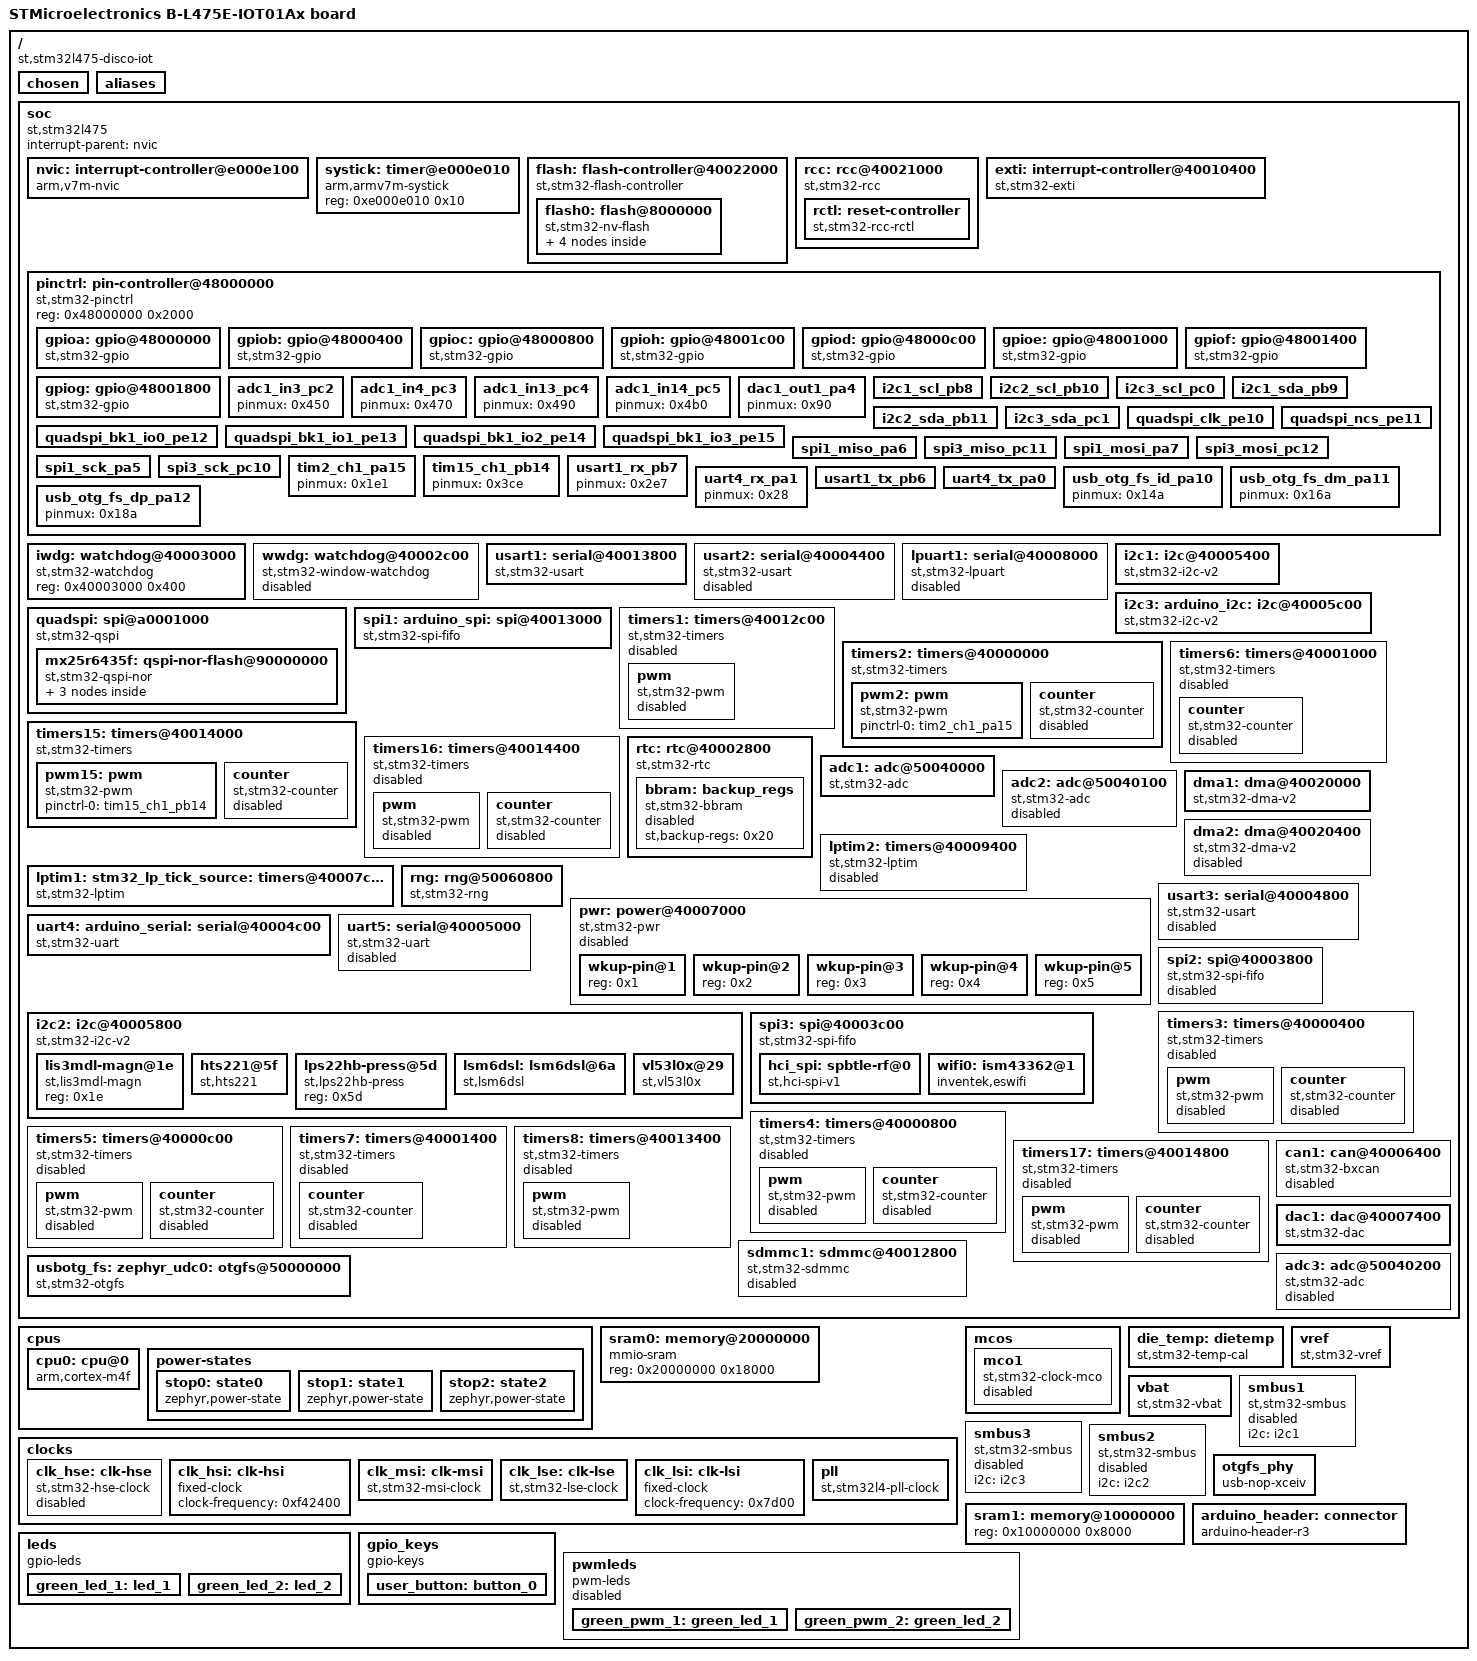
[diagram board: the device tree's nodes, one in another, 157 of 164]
/dts-v1/;

/ {
	#address-cells = < 0x1 >;
	#size-cells = < 0x1 >;
	model = "STMicroelectronics B-L475E-IOT01Ax board";
	compatible = "st,stm32l475-disco-iot";
	chosen {
		zephyr,entropy = &rng;
		zephyr,flash-controller = &mx25r6435f;
		zephyr,console = &usart1;
		zephyr,shell-uart = &usart1;
		zephyr,sram = &sram0;
		zephyr,flash = &flash0;
		zephyr,code-partition = &slot0_partition;
		zephyr,bt-c2h-uart = &usart1;
		zephyr,bt-hci = &hci_spi;
	};
	aliases {
		led0 = &green_led_2;
		led1 = &green_led_1;
		pwm-led0 = &green_pwm_2;
		pwm-led1 = &green_pwm_1;
		sw0 = &user_button;
		eswifi0 = &wifi0;
		watchdog0 = &iwdg;
		accel0 = &lsm6dsl;
		volt-sensor0 = &vref;
		volt-sensor1 = &vbat;
		die-temp0 = &die_temp;
	};
	soc {
		#address-cells = < 0x1 >;
		#size-cells = < 0x1 >;
		compatible = "st,stm32l475", "st,stm32l4", "simple-bus";
		interrupt-parent = < &nvic >;
		ranges;
		nvic: interrupt-controller@e000e100 {
			#address-cells = < 0x1 >;
			compatible = "arm,v7m-nvic";
			reg = < 0xe000e100 0xc00 >;
			interrupt-controller;
			#interrupt-cells = < 0x2 >;
			arm,num-irq-priority-bits = < 0x4 >;
			phandle = < 0x1 >;
		};
		systick: timer@e000e010 {
			compatible = "arm,armv7m-systick";
			reg = < 0xe000e010 0x10 >;
		};
		flash: flash-controller@40022000 {
			compatible = "st,stm32-flash-controller", "st,stm32l4-flash-controller";
			reg = < 0x40022000 0x400 >;
			interrupts = < 0x4 0x0 >;
			clocks = < &rcc 0x48 0x100 >;
			#address-cells = < 0x1 >;
			#size-cells = < 0x1 >;
			flash0: flash@8000000 {
				compatible = "st,stm32-nv-flash", "soc-nv-flash";
				write-block-size = < 0x8 >;
				erase-block-size = < 0x800 >;
				max-erase-time = < 0x19 >;
				reg = < 0x8000000 0x100000 >;
				partitions {
					compatible = "fixed-partitions";
					#address-cells = < 0x1 >;
					#size-cells = < 0x1 >;
					boot_partition: partition@0 {
						label = "mcuboot";
						reg = < 0x0 0x10000 >;
						read-only;
					};
					slot0_partition: partition@1000 {
						label = "image-0";
						reg = < 0x1000 0xe8000 >;
					};
					storage_partition: partition@f8000 {
						label = "storage";
						reg = < 0xf8000 0x8000 >;
					};
				};
			};
		};
		rcc: rcc@40021000 {
			compatible = "st,stm32-rcc";
			#clock-cells = < 0x2 >;
			reg = < 0x40021000 0x400 >;
			clocks = < &pll >;
			clock-frequency = < 0x4c4b400 >;
			ahb-prescaler = < 0x1 >;
			apb1-prescaler = < 0x1 >;
			apb2-prescaler = < 0x1 >;
			phandle = < 0x2 >;
			rctl: reset-controller {
				compatible = "st,stm32-rcc-rctl";
				#reset-cells = < 0x1 >;
				phandle = < 0x4 >;
			};
		};
		exti: interrupt-controller@40010400 {
			compatible = "st,stm32-exti";
			interrupt-controller;
			#interrupt-cells = < 0x1 >;
			#address-cells = < 0x1 >;
			reg = < 0x40010400 0x400 >;
			num-lines = < 0x10 >;
			interrupts = < 0x6 0x0 >, < 0x7 0x0 >, < 0x8 0x0 >, < 0x9 0x0 >, < 0xa 0x0 >, < 0x17 0x0 >, < 0x28 0x0 >;
			interrupt-names = "line0", "line1", "line2", "line3", "line4", "line5-9", "line10-15";
			line-ranges = < 0x0 0x1 >, < 0x1 0x1 >, < 0x2 0x1 >, < 0x3 0x1 >, < 0x4 0x1 >, < 0x5 0x5 >, < 0xa 0x6 >;
		};
		pinctrl: pin-controller@48000000 {
			compatible = "st,stm32-pinctrl";
			#address-cells = < 0x1 >;
			#size-cells = < 0x1 >;
			reg = < 0x48000000 0x2000 >;
			gpioa: gpio@48000000 {
				compatible = "st,stm32-gpio";
				gpio-controller;
				#gpio-cells = < 0x2 >;
				reg = < 0x48000000 0x400 >;
				clocks = < &rcc 0x4c 0x1 >;
				phandle = < 0x15 >;
			};
			gpiob: gpio@48000400 {
				compatible = "st,stm32-gpio";
				gpio-controller;
				#gpio-cells = < 0x2 >;
				reg = < 0x48000400 0x400 >;
				clocks = < &rcc 0x4c 0x2 >;
				phandle = < 0x26 >;
			};
			gpioc: gpio@48000800 {
				compatible = "st,stm32-gpio";
				gpio-controller;
				#gpio-cells = < 0x2 >;
				reg = < 0x48000800 0x400 >;
				clocks = < &rcc 0x4c 0x4 >;
				phandle = < 0x21 >;
			};
			gpioh: gpio@48001c00 {
				compatible = "st,stm32-gpio";
				gpio-controller;
				#gpio-cells = < 0x2 >;
				reg = < 0x48001c00 0x400 >;
				clocks = < &rcc 0x4c 0x80 >;
			};
			gpiod: gpio@48000c00 {
				compatible = "st,stm32-gpio";
				gpio-controller;
				#gpio-cells = < 0x2 >;
				reg = < 0x48000c00 0x400 >;
				clocks = < &rcc 0x4c 0x8 >;
				phandle = < 0x20 >;
			};
			gpioe: gpio@48001000 {
				compatible = "st,stm32-gpio";
				gpio-controller;
				#gpio-cells = < 0x2 >;
				reg = < 0x48001000 0x400 >;
				clocks = < &rcc 0x4c 0x10 >;
				phandle = < 0x25 >;
			};
			gpiof: gpio@48001400 {
				compatible = "st,stm32-gpio";
				gpio-controller;
				#gpio-cells = < 0x2 >;
				reg = < 0x48001400 0x400 >;
				clocks = < &rcc 0x4c 0x20 >;
			};
			gpiog: gpio@48001800 {
				compatible = "st,stm32-gpio";
				gpio-controller;
				#gpio-cells = < 0x2 >;
				reg = < 0x48001800 0x400 >;
				clocks = < &rcc 0x4c 0x40 >;
			};
			adc1_in3_pc2: adc1_in3_pc2 {
				pinmux = < 0x450 >;
				phandle = < 0x18 >;
			};
			adc1_in4_pc3: adc1_in4_pc3 {
				pinmux = < 0x470 >;
				phandle = < 0x19 >;
			};
			adc1_in13_pc4: adc1_in13_pc4 {
				pinmux = < 0x490 >;
				phandle = < 0x1a >;
			};
			adc1_in14_pc5: adc1_in14_pc5 {
				pinmux = < 0x4b0 >;
				phandle = < 0x1b >;
			};
			dac1_out1_pa4: dac1_out1_pa4 {
				pinmux = < 0x90 >;
				phandle = < 0x27 >;
			};
			i2c1_scl_pb8: i2c1_scl_pb8 {
				pinmux = < 0x304 >;
				bias-pull-up;
				drive-open-drain;
				phandle = < 0x7 >;
			};
			i2c2_scl_pb10: i2c2_scl_pb10 {
				pinmux = < 0x344 >;
				bias-pull-up;
				drive-open-drain;
				phandle = < 0x1e >;
			};
			i2c3_scl_pc0: i2c3_scl_pc0 {
				pinmux = < 0x404 >;
				bias-pull-up;
				drive-open-drain;
				phandle = < 0x9 >;
			};
			i2c1_sda_pb9: i2c1_sda_pb9 {
				pinmux = < 0x324 >;
				bias-pull-up;
				drive-open-drain;
				phandle = < 0x8 >;
			};
			i2c2_sda_pb11: i2c2_sda_pb11 {
				pinmux = < 0x364 >;
				bias-pull-up;
				drive-open-drain;
				phandle = < 0x1f >;
			};
			i2c3_sda_pc1: i2c3_sda_pc1 {
				pinmux = < 0x424 >;
				bias-pull-up;
				drive-open-drain;
				phandle = < 0xa >;
			};
			quadspi_clk_pe10: quadspi_clk_pe10 {
				pinmux = < 0x94a >;
				slew-rate = "very-high-speed";
				phandle = < 0xb >;
			};
			quadspi_ncs_pe11: quadspi_ncs_pe11 {
				pinmux = < 0x96a >;
				slew-rate = "very-high-speed";
				phandle = < 0xc >;
			};
			quadspi_bk1_io0_pe12: quadspi_bk1_io0_pe12 {
				pinmux = < 0x98a >;
				slew-rate = "very-high-speed";
				phandle = < 0xd >;
			};
			quadspi_bk1_io1_pe13: quadspi_bk1_io1_pe13 {
				pinmux = < 0x9aa >;
				slew-rate = "very-high-speed";
				phandle = < 0xe >;
			};
			quadspi_bk1_io2_pe14: quadspi_bk1_io2_pe14 {
				pinmux = < 0x9ca >;
				slew-rate = "very-high-speed";
				phandle = < 0xf >;
			};
			quadspi_bk1_io3_pe15: quadspi_bk1_io3_pe15 {
				pinmux = < 0x9ea >;
				slew-rate = "very-high-speed";
				phandle = < 0x10 >;
			};
			spi1_miso_pa6: spi1_miso_pa6 {
				pinmux = < 0xc5 >;
				bias-pull-down;
				phandle = < 0x13 >;
			};
			spi3_miso_pc11: spi3_miso_pc11 {
				pinmux = < 0x566 >;
				bias-pull-down;
				slew-rate = "very-high-speed";
				phandle = < 0x23 >;
			};
			spi1_mosi_pa7: spi1_mosi_pa7 {
				pinmux = < 0xe5 >;
				bias-pull-down;
				phandle = < 0x14 >;
			};
			spi3_mosi_pc12: spi3_mosi_pc12 {
				pinmux = < 0x586 >;
				bias-pull-down;
				phandle = < 0x24 >;
			};
			spi1_sck_pa5: spi1_sck_pa5 {
				pinmux = < 0xa5 >;
				bias-pull-down;
				slew-rate = "very-high-speed";
				phandle = < 0x12 >;
			};
			spi3_sck_pc10: spi3_sck_pc10 {
				pinmux = < 0x546 >;
				bias-pull-down;
				slew-rate = "very-high-speed";
				phandle = < 0x22 >;
			};
			tim2_ch1_pa15: tim2_ch1_pa15 {
				pinmux = < 0x1e1 >;
				phandle = < 0x16 >;
			};
			tim15_ch1_pb14: tim15_ch1_pb14 {
				pinmux = < 0x3ce >;
				phandle = < 0x17 >;
			};
			usart1_rx_pb7: usart1_rx_pb7 {
				pinmux = < 0x2e7 >;
				phandle = < 0x6 >;
			};
			uart4_rx_pa1: uart4_rx_pa1 {
				pinmux = < 0x28 >;
				phandle = < 0x1d >;
			};
			usart1_tx_pb6: usart1_tx_pb6 {
				pinmux = < 0x2c7 >;
				bias-pull-up;
				phandle = < 0x5 >;
			};
			uart4_tx_pa0: uart4_tx_pa0 {
				pinmux = < 0x8 >;
				bias-pull-up;
				phandle = < 0x1c >;
			};
			usb_otg_fs_id_pa10: usb_otg_fs_id_pa10 {
				pinmux = < 0x14a >;
				phandle = < 0x2b >;
			};
			usb_otg_fs_dm_pa11: usb_otg_fs_dm_pa11 {
				pinmux = < 0x16a >;
				phandle = < 0x29 >;
			};
			usb_otg_fs_dp_pa12: usb_otg_fs_dp_pa12 {
				pinmux = < 0x18a >;
				phandle = < 0x2a >;
			};
		};
		iwdg: watchdog@40003000 {
			compatible = "st,stm32-watchdog";
			reg = < 0x40003000 0x400 >;
			status = "okay";
		};
		wwdg: watchdog@40002c00 {
			compatible = "st,stm32-window-watchdog";
			reg = < 0x40002c00 0x400 >;
			clocks = < &rcc 0x58 0x800 >;
			interrupts = < 0x0 0x7 >;
			status = "disabled";
		};
		usart1: serial@40013800 {
			compatible = "st,stm32-usart", "st,stm32-uart";
			reg = < 0x40013800 0x400 >;
			clocks = < &rcc 0x60 0x4000 >;
			resets = < &rctl 0x80e >;
			interrupts = < 0x25 0x0 >;
			status = "okay";
			current-speed = < 0x1c200 >;
			pinctrl-0 = < &usart1_tx_pb6 &usart1_rx_pb7 >;
			pinctrl-names = "default";
		};
		usart2: serial@40004400 {
			compatible = "st,stm32-usart", "st,stm32-uart";
			reg = < 0x40004400 0x400 >;
			clocks = < &rcc 0x58 0x20000 >;
			resets = < &rctl 0x711 >;
			interrupts = < 0x26 0x0 >;
			status = "disabled";
		};
		lpuart1: serial@40008000 {
			compatible = "st,stm32-lpuart", "st,stm32-uart";
			reg = < 0x40008000 0x400 >;
			clocks = < &rcc 0x5c 0x1 >;
			resets = < &rctl 0x780 >;
			interrupts = < 0x46 0x0 >;
			status = "disabled";
		};
		i2c1: i2c@40005400 {
			compatible = "st,stm32-i2c-v2";
			clock-frequency = < 0x61a80 >;
			#address-cells = < 0x1 >;
			#size-cells = < 0x0 >;
			reg = < 0x40005400 0x400 >;
			clocks = < &rcc 0x58 0x200000 >;
			interrupts = < 0x1f 0x0 >, < 0x20 0x0 >;
			interrupt-names = "event", "error";
			status = "okay";
			pinctrl-0 = < &i2c1_scl_pb8 &i2c1_sda_pb9 >;
			pinctrl-names = "default";
			phandle = < 0x31 >;
		};
		i2c3: arduino_i2c: i2c@40005c00 {
			compatible = "st,stm32-i2c-v2";
			clock-frequency = < 0x61a80 >;
			#address-cells = < 0x1 >;
			#size-cells = < 0x0 >;
			reg = < 0x40005c00 0x400 >;
			clocks = < &rcc 0x58 0x800000 >;
			interrupts = < 0x48 0x0 >, < 0x49 0x0 >;
			interrupt-names = "event", "error";
			status = "okay";
			pinctrl-0 = < &i2c3_scl_pc0 &i2c3_sda_pc1 >;
			pinctrl-names = "default";
			phandle = < 0x32 >;
		};
		quadspi: spi@a0001000 {
			compatible = "st,stm32-qspi";
			#address-cells = < 0x1 >;
			#size-cells = < 0x0 >;
			reg = < 0xa0001000 0x400 >;
			interrupts = < 0x47 0x0 >;
			clocks = < &rcc 0x50 0x100 >;
			status = "okay";
			pinctrl-0 = < &quadspi_clk_pe10 &quadspi_ncs_pe11 &quadspi_bk1_io0_pe12 &quadspi_bk1_io1_pe13 &quadspi_bk1_io2_pe14 &quadspi_bk1_io3_pe15 >;
			pinctrl-names = "default";
			dmas = < &dma1 0x5 0x5 0x0 >;
			dma-names = "tx_rx";
			mx25r6435f: qspi-nor-flash@90000000 {
				compatible = "st,stm32-qspi-nor";
				reg = < 0x90000000 0x800000 >;
				qspi-max-frequency = < 0x2faf080 >;
				status = "okay";
				partitions {
					compatible = "fixed-partitions";
					#address-cells = < 0x1 >;
					#size-cells = < 0x1 >;
					slot1_partition: partition@0 {
						label = "image-1";
						reg = < 0x0 0xd8000 >;
					};
					slot2_partition: partition@d8000 {
						label = "image-3";
						reg = < 0xd8000 0x700000 >;
					};
				};
			};
		};
		spi1: arduino_spi: spi@40013000 {
			compatible = "st,stm32-spi-fifo", "st,stm32-spi";
			#address-cells = < 0x1 >;
			#size-cells = < 0x0 >;
			reg = < 0x40013000 0x400 >;
			interrupts = < 0x23 0x5 >;
			clocks = < &rcc 0x60 0x1000 >;
			status = "okay";
			pinctrl-0 = < &spi1_sck_pa5 &spi1_miso_pa6 &spi1_mosi_pa7 >;
			pinctrl-names = "default";
			cs-gpios = < &gpioa 0x2 0x11 >;
		};
		timers1: timers@40012c00 {
			compatible = "st,stm32-timers";
			reg = < 0x40012c00 0x400 >;
			clocks = < &rcc 0x60 0x800 >;
			resets = < &rctl 0x80b >;
			interrupts = < 0x18 0x0 >, < 0x19 0x0 >, < 0x1a 0x0 >, < 0x1b 0x0 >;
			interrupt-names = "brk", "up", "trgcom", "cc";
			st,prescaler = < 0x0 >;
			status = "disabled";
			pwm {
				compatible = "st,stm32-pwm";
				status = "disabled";
				#pwm-cells = < 0x3 >;
			};
		};
		timers2: timers@40000000 {
			compatible = "st,stm32-timers";
			reg = < 0x40000000 0x400 >;
			clocks = < &rcc 0x58 0x1 >;
			resets = < &rctl 0x700 >;
			interrupts = < 0x1c 0x0 >;
			interrupt-names = "global";
			st,prescaler = < 0x2710 >;
			status = "okay";
			pwm2: pwm {
				compatible = "st,stm32-pwm";
				status = "okay";
				#pwm-cells = < 0x3 >;
				pinctrl-0 = < &tim2_ch1_pa15 >;
				pinctrl-names = "default";
				phandle = < 0x34 >;
			};
			counter {
				compatible = "st,stm32-counter";
				status = "disabled";
			};
		};
		timers6: timers@40001000 {
			compatible = "st,stm32-timers";
			reg = < 0x40001000 0x400 >;
			clocks = < &rcc 0x58 0x10 >;
			resets = < &rctl 0x704 >;
			interrupts = < 0x36 0x0 >;
			interrupt-names = "global";
			st,prescaler = < 0x0 >;
			status = "disabled";
			counter {
				compatible = "st,stm32-counter";
				status = "disabled";
			};
		};
		timers15: timers@40014000 {
			compatible = "st,stm32-timers";
			reg = < 0x40014000 0x400 >;
			clocks = < &rcc 0x60 0x10000 >;
			resets = < &rctl 0x810 >;
			interrupts = < 0x18 0x0 >;
			interrupt-names = "global";
			st,prescaler = < 0x2710 >;
			status = "okay";
			pwm15: pwm {
				compatible = "st,stm32-pwm";
				status = "okay";
				#pwm-cells = < 0x3 >;
				pinctrl-0 = < &tim15_ch1_pb14 >;
				pinctrl-names = "default";
				phandle = < 0x35 >;
			};
			counter {
				compatible = "st,stm32-counter";
				status = "disabled";
			};
		};
		timers16: timers@40014400 {
			compatible = "st,stm32-timers";
			reg = < 0x40014400 0x400 >;
			clocks = < &rcc 0x60 0x20000 >;
			resets = < &rctl 0x811 >;
			interrupts = < 0x19 0x0 >;
			interrupt-names = "global";
			st,prescaler = < 0x0 >;
			status = "disabled";
			pwm {
				compatible = "st,stm32-pwm";
				status = "disabled";
				#pwm-cells = < 0x3 >;
			};
			counter {
				compatible = "st,stm32-counter";
				status = "disabled";
			};
		};
		rtc: rtc@40002800 {
			compatible = "st,stm32-rtc";
			reg = < 0x40002800 0x400 >;
			interrupts = < 0x29 0x0 >;
			clocks = < &rcc 0x58 0x10000000 >, < &rcc 0x3 0x10c80090 >;
			prescaler = < 0x8000 >;
			alarms-count = < 0x2 >;
			alrm-exti-line = < 0x12 >;
			status = "okay";
			bbram: backup_regs {
				compatible = "st,stm32-bbram";
				st,backup-regs = < 0x20 >;
				status = "disabled";
			};
		};
		adc1: adc@50040000 {
			compatible = "st,stm32-adc";
			reg = < 0x50040000 0x100 >;
			clocks = < &rcc 0x4c 0x2000 >;
			interrupts = < 0x12 0x0 >;
			status = "okay";
			#io-channel-cells = < 0x1 >;
			resolutions = < 0x60630c 0x51630c 0x42630c 0x33630c >;
			sampling-times = < 0x3 0x7 0xd 0x19 0x30 0x5d 0xf8 0x281 >;
			st,adc-sequencer = "FULLY_CONFIGURABLE";
			st,adc-oversampler = "OVERSAMPLER_MINIMAL";
			pinctrl-0 = < &adc1_in3_pc2 &adc1_in4_pc3 &adc1_in13_pc4 &adc1_in14_pc5 >;
			pinctrl-names = "default";
			st,adc-clock-source = "SYNC";
			st,adc-prescaler = < 0x4 >;
			phandle = < 0x30 >;
		};
		adc2: adc@50040100 {
			compatible = "st,stm32-adc";
			reg = < 0x50040100 0x100 >;
			clocks = < &rcc 0x4c 0x2000 >;
			interrupts = < 0x12 0x0 >;
			status = "disabled";
			#io-channel-cells = < 0x1 >;
			resolutions = < 0x60630c 0x51630c 0x42630c 0x33630c >;
			sampling-times = < 0x3 0x7 0xd 0x19 0x30 0x5d 0xf8 0x281 >;
			st,adc-sequencer = "FULLY_CONFIGURABLE";
			st,adc-oversampler = "OVERSAMPLER_MINIMAL";
		};
		dma1: dma@40020000 {
			compatible = "st,stm32-dma-v2";
			#dma-cells = < 0x3 >;
			reg = < 0x40020000 0x400 >;
			interrupts = < 0xb 0x0 0xc 0x0 0xd 0x0 0xe 0x0 0xf 0x0 0x10 0x0 0x11 0x0 >;
			clocks = < &rcc 0x48 0x1 >;
			dma-requests = < 0x7 >;
			status = "okay";
			phandle = < 0x11 >;
		};
		dma2: dma@40020400 {
			compatible = "st,stm32-dma-v2";
			#dma-cells = < 0x3 >;
			reg = < 0x40020400 0x400 >;
			interrupts = < 0x38 0x0 0x39 0x0 0x3a 0x0 0x3b 0x0 0x3c 0x0 0x44 0x0 0x45 0x0 >;
			clocks = < &rcc 0x48 0x2 >;
			dma-requests = < 0x7 >;
			status = "disabled";
		};
		lptim1: stm32_lp_tick_source: timers@40007c00 {
			compatible = "st,stm32-lptim";
			clocks = < &rcc 0x58 0x80000000 >, < &rcc 0x2 0x18d20088 >;
			#address-cells = < 0x1 >;
			#size-cells = < 0x0 >;
			reg = < 0x40007c00 0x400 >;
			interrupts = < 0x41 0x1 >;
			interrupt-names = "wakeup";
			status = "okay";
		};
		lptim2: timers@40009400 {
			compatible = "st,stm32-lptim";
			#address-cells = < 0x1 >;
			#size-cells = < 0x0 >;
			reg = < 0x40009400 0x400 >;
			clocks = < &rcc 0x5c 0x20 >;
			interrupts = < 0x42 0x1 >;
			interrupt-names = "wakeup";
			status = "disabled";
		};
		rng: rng@50060800 {
			compatible = "st,stm32-rng";
			reg = < 0x50060800 0x400 >;
			interrupts = < 0x50 0x0 >;
			clocks = < &rcc 0x4c 0x40000 >, < &rcc 0x6 0x18da0088 >;
			status = "okay";
		};
		pwr: power@40007000 {
			compatible = "st,stm32-pwr";
			reg = < 0x40007000 0x400 >;
			status = "disabled";
			wkup-pins-nb = < 0x5 >;
			wkup-pins-pol;
			wkup-pins-pupd;
			#address-cells = < 0x1 >;
			#size-cells = < 0x0 >;
			wkup-pin@1 {
				reg = < 0x1 >;
			};
			wkup-pin@2 {
				reg = < 0x2 >;
			};
			wkup-pin@3 {
				reg = < 0x3 >;
			};
			wkup-pin@4 {
				reg = < 0x4 >;
			};
			wkup-pin@5 {
				reg = < 0x5 >;
			};
		};
		usart3: serial@40004800 {
			compatible = "st,stm32-usart", "st,stm32-uart";
			reg = < 0x40004800 0x400 >;
			clocks = < &rcc 0x58 0x40000 >;
			resets = < &rctl 0x712 >;
			interrupts = < 0x27 0x0 >;
			status = "disabled";
		};
		uart4: arduino_serial: serial@40004c00 {
			compatible = "st,stm32-uart";
			reg = < 0x40004c00 0x400 >;
			clocks = < &rcc 0x58 0x80000 >;
			resets = < &rctl 0x713 >;
			interrupts = < 0x34 0x0 >;
			status = "okay";
			pinctrl-0 = < &uart4_tx_pa0 &uart4_rx_pa1 >;
			pinctrl-names = "default";
			current-speed = < 0x1c200 >;
		};
		uart5: serial@40005000 {
			compatible = "st,stm32-uart";
			reg = < 0x40005000 0x400 >;
			clocks = < &rcc 0x58 0x100000 >;
			resets = < &rctl 0x714 >;
			interrupts = < 0x35 0x0 >;
			status = "disabled";
		};
		i2c2: i2c@40005800 {
			compatible = "st,stm32-i2c-v2";
			clock-frequency = < 0x61a80 >;
			#address-cells = < 0x1 >;
			#size-cells = < 0x0 >;
			reg = < 0x40005800 0x400 >;
			clocks = < &rcc 0x58 0x400000 >;
			interrupts = < 0x21 0x0 >, < 0x22 0x0 >;
			interrupt-names = "event", "error";
			status = "okay";
			pinctrl-0 = < &i2c2_scl_pb10 &i2c2_sda_pb11 >;
			pinctrl-names = "default";
			phandle = < 0x33 >;
			lis3mdl-magn@1e {
				compatible = "st,lis3mdl-magn";
				reg = < 0x1e >;
			};
			hts221@5f {
				compatible = "st,hts221";
				reg = < 0x5f >;
				drdy-gpios = < &gpiod 0xf 0x0 >;
			};
			lps22hb-press@5d {
				compatible = "st,lps22hb-press";
				reg = < 0x5d >;
			};
			lsm6dsl: lsm6dsl@6a {
				compatible = "st,lsm6dsl";
				reg = < 0x6a >;
				irq-gpios = < &gpiod 0xb 0x0 >;
			};
			vl53l0x@29 {
				compatible = "st,vl53l0x";
				reg = < 0x29 >;
				xshut-gpios = < &gpioc 0x6 0x1 >;
			};
		};
		spi2: spi@40003800 {
			compatible = "st,stm32-spi-fifo", "st,stm32-spi";
			#address-cells = < 0x1 >;
			#size-cells = < 0x0 >;
			reg = < 0x40003800 0x400 >;
			clocks = < &rcc 0x58 0x4000 >;
			interrupts = < 0x24 0x5 >;
			status = "disabled";
		};
		spi3: spi@40003c00 {
			compatible = "st,stm32-spi-fifo", "st,stm32-spi";
			#address-cells = < 0x1 >;
			#size-cells = < 0x0 >;
			reg = < 0x40003c00 0x400 >;
			clocks = < &rcc 0x58 0x8000 >;
			interrupts = < 0x33 0x5 >;
			status = "okay";
			pinctrl-0 = < &spi3_sck_pc10 &spi3_miso_pc11 &spi3_mosi_pc12 >;
			pinctrl-names = "default";
			cs-gpios = < &gpiod 0xd 0x1 >, < &gpioe 0x0 0x1 >;
			hci_spi: spbtle-rf@0 {
				compatible = "st,hci-spi-v1";
				reg = < 0x0 >;
				reset-gpios = < &gpioa 0x8 0x1 >;
				irq-gpios = < &gpioe 0x6 0x20 >;
				spi-max-frequency = < 0x1e8480 >;
				spi-hold-cs;
			};
			wifi0: ism43362@1 {
				compatible = "inventek,eswifi";
				spi-max-frequency = < 0x1e8480 >;
				reg = < 0x1 >;
				resetn-gpios = < &gpioe 0x8 0x0 >;
				boot0-gpios = < &gpiob 0xc 0x0 >;
				wakeup-gpios = < &gpiob 0xd 0x0 >;
				data-gpios = < &gpioe 0x1 0x0 >;
			};
		};
		timers3: timers@40000400 {
			compatible = "st,stm32-timers";
			reg = < 0x40000400 0x400 >;
			clocks = < &rcc 0x58 0x2 >;
			resets = < &rctl 0x701 >;
			interrupts = < 0x1d 0x0 >;
			interrupt-names = "global";
			st,prescaler = < 0x0 >;
			status = "disabled";
			pwm {
				compatible = "st,stm32-pwm";
				status = "disabled";
				#pwm-cells = < 0x3 >;
			};
			counter {
				compatible = "st,stm32-counter";
				status = "disabled";
			};
		};
		timers4: timers@40000800 {
			compatible = "st,stm32-timers";
			reg = < 0x40000800 0x400 >;
			clocks = < &rcc 0x58 0x4 >;
			resets = < &rctl 0x702 >;
			interrupts = < 0x1e 0x0 >;
			interrupt-names = "global";
			st,prescaler = < 0x0 >;
			status = "disabled";
			pwm {
				compatible = "st,stm32-pwm";
				status = "disabled";
				#pwm-cells = < 0x3 >;
			};
			counter {
				compatible = "st,stm32-counter";
				status = "disabled";
			};
		};
		timers5: timers@40000c00 {
			compatible = "st,stm32-timers";
			reg = < 0x40000c00 0x400 >;
			clocks = < &rcc 0x58 0x8 >;
			resets = < &rctl 0x703 >;
			interrupts = < 0x32 0x0 >;
			interrupt-names = "global";
			st,prescaler = < 0x0 >;
			status = "disabled";
			pwm {
				compatible = "st,stm32-pwm";
				status = "disabled";
				#pwm-cells = < 0x3 >;
			};
			counter {
				compatible = "st,stm32-counter";
				status = "disabled";
			};
		};
		timers7: timers@40001400 {
			compatible = "st,stm32-timers";
			reg = < 0x40001400 0x400 >;
			clocks = < &rcc 0x58 0x20 >;
			resets = < &rctl 0x705 >;
			interrupts = < 0x37 0x0 >;
			interrupt-names = "global";
			st,prescaler = < 0x0 >;
			status = "disabled";
			counter {
				compatible = "st,stm32-counter";
				status = "disabled";
			};
		};
		timers8: timers@40013400 {
			compatible = "st,stm32-timers";
			reg = < 0x40013400 0x400 >;
			clocks = < &rcc 0x60 0x2000 >;
			resets = < &rctl 0x80d >;
			interrupts = < 0x2b 0x0 >, < 0x2c 0x0 >, < 0x2d 0x0 >, < 0x2e 0x0 >;
			interrupt-names = "brk", "up", "trgcom", "cc";
			st,prescaler = < 0x0 >;
			status = "disabled";
			pwm {
				compatible = "st,stm32-pwm";
				status = "disabled";
				#pwm-cells = < 0x3 >;
			};
		};
		timers17: timers@40014800 {
			compatible = "st,stm32-timers";
			reg = < 0x40014800 0x400 >;
			clocks = < &rcc 0x60 0x40000 >;
			resets = < &rctl 0x812 >;
			interrupts = < 0x1a 0x0 >;
			interrupt-names = "global";
			st,prescaler = < 0x0 >;
			status = "disabled";
			pwm {
				compatible = "st,stm32-pwm";
				status = "disabled";
				#pwm-cells = < 0x3 >;
			};
			counter {
				compatible = "st,stm32-counter";
				status = "disabled";
			};
		};
		can1: can@40006400 {
			compatible = "st,stm32-bxcan";
			reg = < 0x40006400 0x400 >;
			interrupts = < 0x13 0x0 >, < 0x14 0x0 >, < 0x15 0x0 >, < 0x16 0x0 >;
			interrupt-names = "TX", "RX0", "RX1", "SCE";
			clocks = < &rcc 0x58 0x2000000 >;
			status = "disabled";
		};
		sdmmc1: sdmmc@40012800 {
			compatible = "st,stm32-sdmmc";
			reg = < 0x40012800 0x400 >;
			clocks = < &rcc 0x60 0x400 >, < &rcc 0x6 0x18da0088 >;
			resets = < &rctl 0x80a >;
			interrupts = < 0x31 0x0 >;
			status = "disabled";
		};
		dac1: dac@40007400 {
			compatible = "st,stm32-dac";
			reg = < 0x40007400 0x400 >;
			clocks = < &rcc 0x58 0x20000000 >;
			status = "okay";
			#io-channel-cells = < 0x1 >;
			pinctrl-0 = < &dac1_out1_pa4 >;
			pinctrl-names = "default";
		};
		adc3: adc@50040200 {
			compatible = "st,stm32-adc";
			reg = < 0x50040200 0x100 >;
			clocks = < &rcc 0x4c 0x2000 >;
			interrupts = < 0x2f 0x0 >;
			status = "disabled";
			#io-channel-cells = < 0x1 >;
		};
		usbotg_fs: zephyr_udc0: otgfs@50000000 {
			compatible = "st,stm32-otgfs";
			reg = < 0x50000000 0x40000 >;
			interrupts = < 0x43 0x0 >;
			interrupt-names = "otgfs";
			num-bidir-endpoints = < 0x6 >;
			ram-size = < 0x500 >;
			maximum-speed = "full-speed";
			phys = < &otgfs_phy >;
			clocks = < &rcc 0x4c 0x1000 >, < &rcc 0x6 0x18da0088 >;
			status = "okay";
			pinctrl-0 = < &usb_otg_fs_dm_pa11 &usb_otg_fs_dp_pa12 &usb_otg_fs_id_pa10 >;
			pinctrl-names = "default";
		};
	};
	cpus {
		#address-cells = < 0x1 >;
		#size-cells = < 0x0 >;
		cpu0: cpu@0 {
			device_type = "cpu";
			compatible = "arm,cortex-m4f";
			reg = < 0x0 >;
			cpu-power-states = < &stop0 &stop1 &stop2 >;
		};
		power-states {
			stop0: state0 {
				compatible = "zephyr,power-state";
				power-state-name = "suspend-to-idle";
				substate-id = < 0x1 >;
				min-residency-us = < 0x1f4 >;
				phandle = < 0x2c >;
			};
			stop1: state1 {
				compatible = "zephyr,power-state";
				power-state-name = "suspend-to-idle";
				substate-id = < 0x2 >;
				min-residency-us = < 0x2bc >;
				phandle = < 0x2d >;
			};
			stop2: state2 {
				compatible = "zephyr,power-state";
				power-state-name = "suspend-to-idle";
				substate-id = < 0x3 >;
				min-residency-us = < 0x3e8 >;
				phandle = < 0x2e >;
			};
		};
	};
	sram0: memory@20000000 {
		compatible = "mmio-sram";
		reg = < 0x20000000 0x18000 >;
	};
	clocks {
		clk_hse: clk-hse {
			#clock-cells = < 0x0 >;
			compatible = "st,stm32-hse-clock";
			status = "disabled";
		};
		clk_hsi: clk-hsi {
			#clock-cells = < 0x0 >;
			compatible = "fixed-clock";
			clock-frequency = < 0xf42400 >;
			status = "okay";
			phandle = < 0x2f >;
		};
		clk_msi: clk-msi {
			#clock-cells = < 0x0 >;
			compatible = "st,stm32-msi-clock";
			msi-range = < 0xb >;
			status = "okay";
			msi-pll-mode;
		};
		clk_lse: clk-lse {
			#clock-cells = < 0x0 >;
			compatible = "st,stm32-lse-clock";
			clock-frequency = < 0x8000 >;
			driving-capability = < 0x0 >;
			status = "okay";
		};
		clk_lsi: clk-lsi {
			#clock-cells = < 0x0 >;
			compatible = "fixed-clock";
			clock-frequency = < 0x7d00 >;
			status = "okay";
		};
		pll: pll {
			#clock-cells = < 0x0 >;
			compatible = "st,stm32l4-pll-clock";
			status = "okay";
			div-m = < 0x1 >;
			mul-n = < 0x14 >;
			div-p = < 0x7 >;
			div-q = < 0x2 >;
			div-r = < 0x4 >;
			clocks = < &clk_hsi >;
			phandle = < 0x3 >;
		};
	};
	mcos {
		mco1: mco1 {
			compatible = "st,stm32-clock-mco";
			status = "disabled";
		};
	};
	die_temp: dietemp {
		compatible = "st,stm32-temp-cal";
		ts-cal1-addr = < 0x1fff75a8 >;
		ts-cal2-addr = < 0x1fff75ca >;
		ts-cal1-temp = < 0x1e >;
		ts-cal2-temp = < 0x6e >;
		ts-cal-vrefanalog = < 0xbb8 >;
		io-channels = < &adc1 0x11 >;
		status = "okay";
	};
	vref: vref {
		compatible = "st,stm32-vref";
		vrefint-cal-addr = < 0x1fff75aa >;
		vrefint-cal-mv = < 0xbb8 >;
		io-channels = < &adc1 0x0 >;
		status = "okay";
	};
	vbat: vbat {
		compatible = "st,stm32-vbat";
		ratio = < 0x3 >;
		io-channels = < &adc1 0x12 >;
		status = "okay";
	};
	smbus1: smbus1 {
		compatible = "st,stm32-smbus";
		#address-cells = < 0x1 >;
		#size-cells = < 0x0 >;
		i2c = < &i2c1 >;
		status = "disabled";
	};
	smbus3: smbus3 {
		compatible = "st,stm32-smbus";
		#address-cells = < 0x1 >;
		#size-cells = < 0x0 >;
		i2c = < &i2c3 >;
		status = "disabled";
	};
	smbus2: smbus2 {
		compatible = "st,stm32-smbus";
		#address-cells = < 0x1 >;
		#size-cells = < 0x0 >;
		i2c = < &i2c2 >;
		status = "disabled";
	};
	otgfs_phy: otgfs_phy {
		compatible = "usb-nop-xceiv";
		#phy-cells = < 0x0 >;
		phandle = < 0x28 >;
	};
	sram1: memory@10000000 {
		reg = < 0x10000000 0x8000 >;
	};
	arduino_header: connector {
		compatible = "arduino-header-r3";
		#gpio-cells = < 0x2 >;
		gpio-map-mask = < 0xffffffff 0xffffffc0 >;
		gpio-map-pass-thru = < 0x0 0x3f >;
		gpio-map = < 0x0 0x0 &gpioc 0x5 0x0 >, < 0x1 0x0 &gpioc 0x4 0x0 >, < 0x2 0x0 &gpioc 0x3 0x0 >, < 0x3 0x0 &gpioc 0x2 0x0 >, < 0x4 0x0 &gpioc 0x1 0x0 >, < 0x5 0x0 &gpioc 0x0 0x0 >, < 0x6 0x0 &gpioa 0x1 0x0 >, < 0x7 0x0 &gpioa 0x0 0x0 >, < 0x8 0x0 &gpiod 0xe 0x0 >, < 0x9 0x0 &gpiob 0x0 0x0 >, < 0xa 0x0 &gpioa 0x3 0x0 >, < 0xb 0x0 &gpiob 0x4 0x0 >, < 0xc 0x0 &gpiob 0x1 0x0 >, < 0xd 0x0 &gpioa 0x4 0x0 >, < 0xe 0x0 &gpiob 0x2 0x0 >, < 0xf 0x0 &gpioa 0xf 0x0 >, < 0x10 0x0 &gpioa 0x2 0x0 >, < 0x11 0x0 &gpioa 0x7 0x0 >, < 0x12 0x0 &gpioa 0x6 0x0 >, < 0x13 0x0 &gpioa 0x5 0x0 >, < 0x14 0x0 &gpiob 0x9 0x0 >, < 0x15 0x0 &gpiob 0x8 0x0 >;
	};
	leds {
		compatible = "gpio-leds";
		green_led_1: led_1 {
			gpios = < &gpioa 0x5 0x0 >;
			label = "User LD1";
		};
		green_led_2: led_2 {
			gpios = < &gpiob 0xe 0x0 >;
			label = "User LD2";
		};
	};
	gpio_keys {
		compatible = "gpio-keys";
		user_button: button_0 {
			label = "User";
			gpios = < &gpioc 0xd 0x1 >;
			zephyr,code = < 0xb >;
		};
	};
	pwmleds: pwmleds {
		compatible = "pwm-leds";
		status = "disabled";
		green_pwm_1: green_led_1 {
			pwms = < &pwm2 0x1 0x1312d00 0x0 >;
			label = "green LD1";
		};
		green_pwm_2: green_led_2 {
			pwms = < &pwm15 0x1 0x1312d00 0x0 >;
			label = "green LD2";
		};
	};
};
